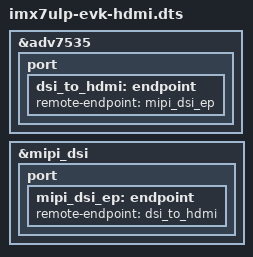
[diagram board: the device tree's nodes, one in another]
/*
 * Copyright 2017 NXP.
 *
 * This program is free software; you can redistribute it and/or modify
 * it under the terms of the GNU General Public License version 2 as
 * published by the Free Software Foundation.
 */

#include "imx7ulp-evk.dts"

&adv7535 {
	status = "okay";
	port {
		dsi_to_hdmi: endpoint {
			remote-endpoint = <&mipi_dsi_ep>;
		};
	};
};

&mipi_dsi {
	port {
		mipi_dsi_ep: endpoint {
			remote-endpoint = <&dsi_to_hdmi>;
		};
	};
};
